# STM32WBA23 register map
File version: 1.0
CPU: CM33 r0p1, little endian, MPU, FPU, 4 interrupt priority bits
Registers are 32-bit, read-write, reset 0x0 unless marked. A register's access mark holds for its fields unless they carry their own. Offsets are from the block's base; [hi:lo] are bit positions; {n}, {i} and the like mark numbered series; 'fields as' and 'values as' point back to an identical list.

## GTZC1_MPCBB1 — GTZC1_MPCBB1 address block description
Base 0x40032C00
Same registers: SEC_GTZC1_MPCBB1 0x50032C00
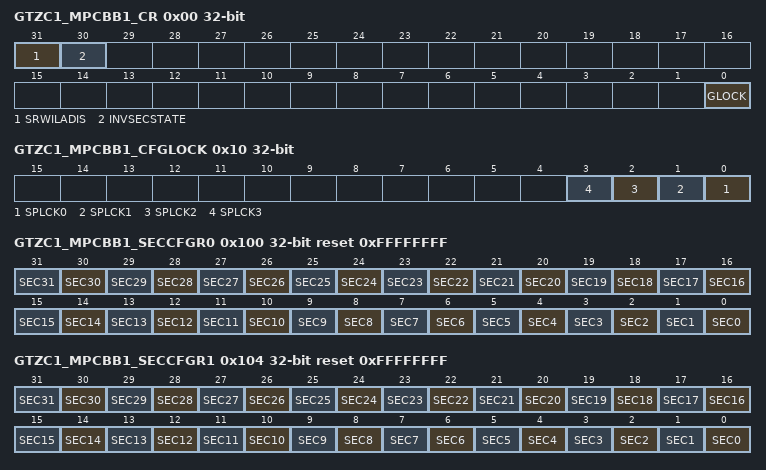
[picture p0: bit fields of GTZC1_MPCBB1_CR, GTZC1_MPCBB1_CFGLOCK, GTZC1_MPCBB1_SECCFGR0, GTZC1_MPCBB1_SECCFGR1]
0x00 GTZC1_MPCBB1_CR — GTZC1 MPCBB control register
  [31] SRWILADIS — secure read/write illegal access disable
    0=enabled, secure read/write acces not allowed on nonsecure SRAMx block; 1=disabled, secure read/write access allowed on nonsecure SRAMx block
  [30] INVSECSTATE — SRAM clocks security state
    0=SRAM clock is secured if a secure area exists in the MPCBBx; 1=SRAM clock is nonsecure even if a secure area exists in the MPCBBx, and secure even if no secure block is set in the MPCBBx
  [0] GLOCK — Lock the control register of the MPCBBx until next reset
    0=Control register not locked; 1=Control register locked
0x10 GTZC1_MPCBB1_CFGLOCK (alternate view of GTZC1_TZSC_SECCFGR1) — GTZC1 MPCBB1 configuration lock register
  [all] fields
    0=GTZC1_MPCBB1_SECCFGRn and GTZC1_MPCBB1_PRIVCFGRn can be written; 1=Writes to GTZC1_MPCBB1_SECCFGRn and GTZC1_MPCBB1_PRIVCFGRn are ignored
  [n] SPLCK{n} (n=0..3) — Security/privilege configuration lock super-block
0x100 GTZC1_MPCBB1_SECCFGR0 reset 0xFFFFFFFF — GTZC1 MPCBB security configuration for super-block 0 register
  [all] fields
    0=Nonsecure access only to block y, belonging to super-block n; 1=Secure access only to block y, belonging to super-block n
  [n] SEC{n} (n=0..31) — Security configuration for block y (y = 0 to 31) in super block n
0x104 GTZC1_MPCBB1_SECCFGR1 reset 0xFFFFFFFF — GTZC1 MPCBB security configuration for super-block 1 register
  fields as GTZC1_MPCBB1_SECCFGR0
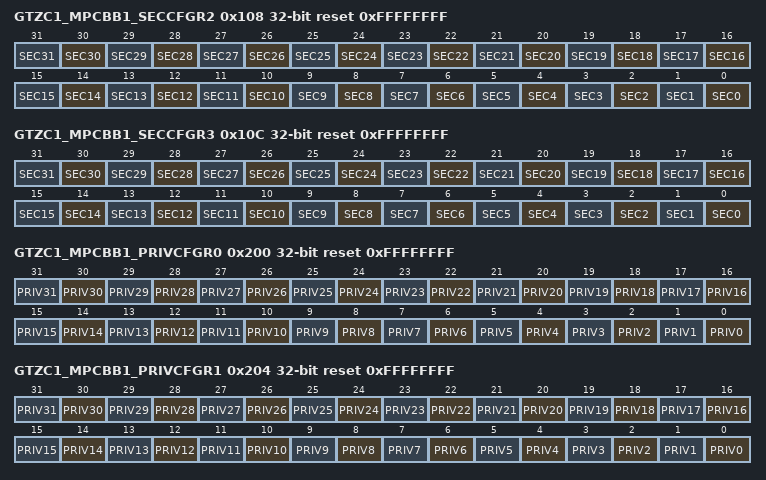
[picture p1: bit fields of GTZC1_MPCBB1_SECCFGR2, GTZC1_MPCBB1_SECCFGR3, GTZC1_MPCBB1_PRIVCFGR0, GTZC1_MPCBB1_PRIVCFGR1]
0x108 GTZC1_MPCBB1_SECCFGR2 reset 0xFFFFFFFF — GTZC1 MPCBB1 security configuration for super-block 2 register
  fields as GTZC1_MPCBB1_SECCFGR0
0x10C GTZC1_MPCBB1_SECCFGR3 reset 0xFFFFFFFF — GTZC1 MPCBB1 security configuration for super-block 3 register
  fields as GTZC1_MPCBB1_SECCFGR0
0x200 GTZC1_MPCBB1_PRIVCFGR0 reset 0xFFFFFFFF — GTZC1 MPCBB privileged configuration for super-block 0 register
  [all] fields
    0=Privileged and unprivileged access to block y, belonging to super-block n; 1=Only privileged access to block y, belonging to super-block n
  [n] PRIV{n} (n=0..31) — Privileged configuration for block y (y = 0 to 31), belonging to super-block n.
0x204 GTZC1_MPCBB1_PRIVCFGR1 reset 0xFFFFFFFF — GTZC1 MPCBB privileged configuration for super-block 1 register
  fields as GTZC1_MPCBB1_PRIVCFGR0
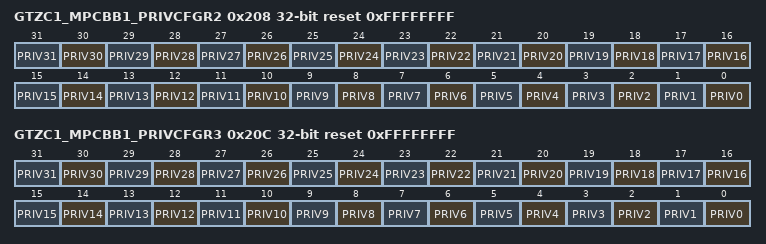
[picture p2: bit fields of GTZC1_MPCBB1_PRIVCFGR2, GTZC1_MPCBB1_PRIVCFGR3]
0x208 GTZC1_MPCBB1_PRIVCFGR2 reset 0xFFFFFFFF — GTZC1 MPCBB1 privileged configuration for super-block 2 register
  fields as GTZC1_MPCBB1_PRIVCFGR0
0x20C GTZC1_MPCBB1_PRIVCFGR3 reset 0xFFFFFFFF — GTZC1 MPCBB1 privileged configuration for super-block 3 register
  fields as GTZC1_MPCBB1_PRIVCFGR0

## GTZC1_MPCBB2 — GTZC1_MPCBB2 address block description
Base 0x40033000
Same registers: SEC_GTZC1_MPCBB2 0x50033000
Registers as GTZC1_MPCBB1 (with GTZC1_MPCBB1 read as GTZC1_MPCBB2), without GTZC1_MPCBB1_SECCFGR2, GTZC1_MPCBB1_SECCFGR3, GTZC1_MPCBB1_PRIVCFGR2, GTZC1_MPCBB1_PRIVCFGR3; these are added or differ:
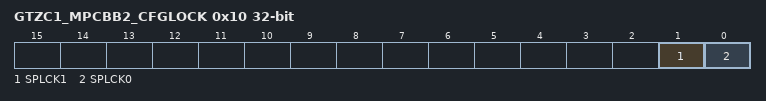
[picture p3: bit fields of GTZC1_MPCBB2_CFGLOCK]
0x10 GTZC1_MPCBB2_CFGLOCK (alternate view of GTZC1_TZSC_SECCFGR1) — GTZC1 MPCBB2 configuration lock register
  [1] SPLCK1 — Security/privilege configuration lock super-block
    0=GTZC1_MPCBB2_SECCFGRn and GTZC1_MPCBB2_PRIVCFGRn can be written; 1=Writes to GTZC1_MPCBB2_SECCFGRn and GTZC1_MPCBB2_PRIVCFGRn are ignored
  [0] SPLCK0 — Security/privilege configuration lock super-block
    values as SPLCK1

## HASH — HASH address block description
Base 0x420C0400
Same registers: SEC_HASH 0x520C0400
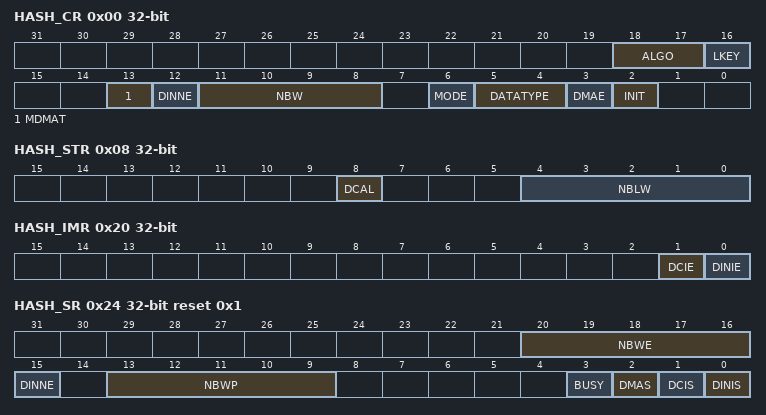
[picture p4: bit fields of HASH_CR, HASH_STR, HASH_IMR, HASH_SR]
0x00 HASH_CR — HASH control register
  [18:17] ALGO — Algorithm selection
    0=SHA-1; 2=SHA2-224; 3=SHA2-256
  [16] LKEY — Long key selection
    0=the HMAC key is shorter or equal to 64 bytes; 1=the HMAC key is longer than 64 bytes
  [13] MDMAT — Multiple DMA transfers
    0=DCAL is automatically set at the end of a DMA transfer; 1=DCAL is not automatically set at the end of a DMA transfer
  [12] DINNE ro — DIN not empty
  [11:8] NBW ro — Number of words already pushed
  [6] MODE — Mode selection
    0=Hash mode selected; 1=HMAC mode selected
  [5:4] DATATYPE — Data type selection
    0=32-bit data; 1=16-bit data, or half-word; 2=8-bit data, or bytes; 3=bit data, or bit-string
  [3] DMAE — DMA enable
    0=DMA transfers disabled; 1=DMA transfers enabled
  [2] INIT — Initialize message digest calculation
0x04 HASH_DIN wo — HASH data input register
  [31:0] DATAIN — Data input
0x08 HASH_STR — HASH start register
  [8] DCAL — Digest calculation
  [4:0] NBLW — Number of valid bits in the last word
    0=All 32 bits of the last data written are valid message bits that is M[31:0]; 1=Only one bit of the last data written (after swapping) is valid that is M[0]; 2=Only two bits of the last data written (after swapping) are valid that is M[1:0]; 3=Only three bits of the last data written (after swapping) are valid that is M[2:0]; 31=Only 31 bits of the last data written (after swapping) are valid that is M[30:0]
{0xC+4i} HASH_HRA{i} ro (i=0..4) — HASH aliased digest register {i}
  [31:0] H{i} — Hash data x
0x20 HASH_IMR — HASH interrupt enable register
  [1] DCIE — Digest calculation completion interrupt enable
    0=Digest calculation completion interrupt disabled; 1=Digest calculation completion interrupt enabled
  [0] DINIE — Data input interrupt enable
    0=Data input interrupt disabled; 1=Data input interrupt enabled
0x24 HASH_SR reset 0x1 — HASH status register
  [20:16] NBWE ro — Number of words expected
  [15] DINNE ro — DIN not empty
    0=No data are present in the data input buffer; 1=The input buffer contains at least one word of data
  [13:9] NBWP ro — Number of words already pushed
  [3] BUSY ro — Busy bit
    0=No block is currently being processed; 1=The hash core is processing a block of data
  [2] DMAS ro — DMA Status
    0=DMA interface is disabled (DMAE=0) and no transfer is ongoing; 1=DMA interface is enabled (DMAE=1) or a transfer is ongoing
  [1] DCIS — Digest calculation completion interrupt status
    0=No digest available in the HASH_HRx registers (zeros are returned); 1=Digest calculation complete, a digest is available in the HASH_HRx registers
  [0] DINIS — Data input interrupt status
    0=Less than 16 locations are free in the input buffer; 1=A new block can be entered into the input buffer
{0xF8+4i} HASH_CSR{i} (i=0..53) — HASH context swap register {i}
  [31:0] CS{i} — Context swap x
{0x310+4i} HASH_HR{i} ro (i=0..4) — HASH digest register {i}
  [31:0] H{i} — Hash data x
{0x310+4i} HASH_HR{i} ro (i=5..7) — HASH supplementary digest register {i}
  [31:0] H{i} — Hash data x
